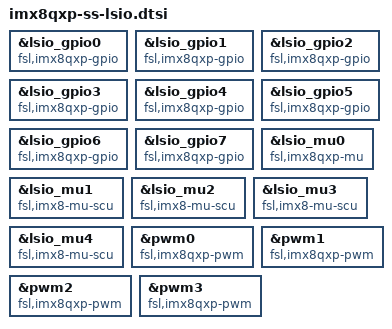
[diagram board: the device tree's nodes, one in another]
// SPDX-License-Identifier: GPL-2.0+
/*
 * Copyright 2018-2019 NXP
 *	Dong Aisheng <aisheng.dong@nxp.com>
 */

&lsio_gpio0 {
	compatible = "fsl,imx8qxp-gpio", "fsl,imx35-gpio";
};

&lsio_gpio1 {
	compatible = "fsl,imx8qxp-gpio", "fsl,imx35-gpio";
};

&lsio_gpio2 {
	compatible = "fsl,imx8qxp-gpio", "fsl,imx35-gpio";
};

&lsio_gpio3 {
	compatible = "fsl,imx8qxp-gpio", "fsl,imx35-gpio";
};

&lsio_gpio4 {
	compatible = "fsl,imx8qxp-gpio", "fsl,imx35-gpio";
};

&lsio_gpio5 {
	compatible = "fsl,imx8qxp-gpio", "fsl,imx35-gpio";
};

&lsio_gpio6 {
	compatible = "fsl,imx8qxp-gpio", "fsl,imx35-gpio";
};

&lsio_gpio7 {
	compatible = "fsl,imx8qxp-gpio", "fsl,imx35-gpio";
};

&lsio_mu0 {
	compatible = "fsl,imx8qxp-mu", "fsl,imx6sx-mu";
};

&lsio_mu1 {
	compatible = "fsl,imx8-mu-scu", "fsl,imx8qxp-mu", "fsl,imx6sx-mu";
};

&lsio_mu2 {
	compatible = "fsl,imx8-mu-scu", "fsl,imx8qxp-mu", "fsl,imx6sx-mu";
};

&lsio_mu3 {
	compatible = "fsl,imx8-mu-scu", "fsl,imx8qxp-mu", "fsl,imx6sx-mu";
};

&lsio_mu4 {
	compatible = "fsl,imx8-mu-scu", "fsl,imx8qxp-mu", "fsl,imx6sx-mu";
};

&pwm0 {
		compatible = "fsl,imx8qxp-pwm", "fsl,imx27-pwm";
};

&pwm1 {
		compatible = "fsl,imx8qxp-pwm", "fsl,imx27-pwm";
};

&pwm2 {
		compatible = "fsl,imx8qxp-pwm", "fsl,imx27-pwm";
};

&pwm3 {
		compatible = "fsl,imx8qxp-pwm", "fsl,imx27-pwm";
};
